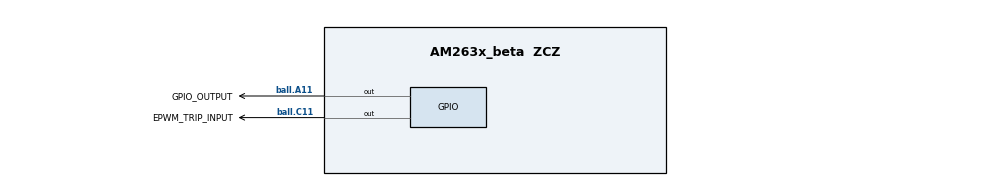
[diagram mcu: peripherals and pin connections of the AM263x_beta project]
/**
 * @cliArgs --device "AM263x_beta" --package "ZCZ" --part "AM263x" --context "r5fss0-0" --product "MCU_PLUS_SDK@07.03.01"
 * @versions {"tool":"1.13.0+2553"}
 */

/**
 * Import the modules used in this configuration.
 */
const epwm        = scripting.addModule("/drivers/epwm/epwm", {}, false);
const epwm1       = epwm.addInstance();
const epwm2       = epwm.addInstance();
const gpio        = scripting.addModule("/drivers/gpio/gpio", {}, false);
const gpio1       = gpio.addInstance();
const gpio2       = gpio.addInstance();
const mpu_armv7   = scripting.addModule("/kernel/dpl/mpu_armv7", {}, false);
const mpu_armv71  = mpu_armv7.addInstance();
const mpu_armv72  = mpu_armv7.addInstance();
const mpu_armv73  = mpu_armv7.addInstance();
const mpu_armv74  = mpu_armv7.addInstance();
const input_xbar  = scripting.addModule("/xbar/input_xbar/input_xbar", {}, false);
const input_xbar1 = input_xbar.addInstance();
const int_xbar    = scripting.addModule("/xbar/int_xbar/int_xbar", {}, false);
const int_xbar1   = int_xbar.addInstance();
const int_xbar2   = int_xbar.addInstance();

/**
 * Write custom configuration values to the imported modules.
 */
epwm1.epwmTimebase_emulationMode                                 = "EPWM_EMULATION_FREE_RUN";
epwm1.epwmTimebase_clockDiv                                      = "EPWM_CLOCK_DIVIDER_4";
epwm1.epwmTimebase_period                                        = 12000;
epwm1.epwmTimebase_counterMode                                   = "EPWM_COUNTER_MODE_UP_DOWN";
epwm1.epwmTimebase_syncOutPulseMode                              = ["EPWM_SYNC_OUT_PULSE_ON_ALL"];
epwm1.epwmCounterCompare_cmpA                                    = 6000;
epwm1.epwmActionQualifier_EPWM_AQ_OUTPUT_A_ON_TIMEBASE_UP_CMPA   = "EPWM_AQ_OUTPUT_HIGH";
epwm1.epwmActionQualifier_EPWM_AQ_OUTPUT_A_ON_TIMEBASE_DOWN_CMPA = "EPWM_AQ_OUTPUT_LOW";
epwm1.epwmEventTrigger_enableInterrupt                           = true;
epwm1.epwmEventTrigger_interruptEventCount                       = "1";
epwm1.epwmTimebase_hsClockDiv                                    = "EPWM_HSCLOCK_DIVIDER_4";
epwm1.epwmTripZone_oneShotSource                                 = ["EPWM_TZ_SIGNAL_OSHT1"];
epwm1.epwmTripZone_tzInterruptSource                             = ["EPWM_TZ_INTERRUPT_OST"];
epwm1.$name                                                      = "CONFIG_EPWMx";
epwm1.EPWM.$assign                                               = "EPWM9";
epwm1.EPWM.B.$used                                               = false;

epwm2.epwmTimebase_clockDiv                                      = "EPWM_CLOCK_DIVIDER_4";
epwm2.epwmTimebase_hsClockDiv                                    = "EPWM_HSCLOCK_DIVIDER_4";
epwm2.epwmTimebase_period                                        = 6000;
epwm2.epwmTimebase_counterMode                                   = "EPWM_COUNTER_MODE_UP_DOWN";
epwm2.epwmTimebase_emulationMode                                 = "EPWM_EMULATION_FREE_RUN";
epwm2.epwmTimebase_syncOutPulseMode                              = ["EPWM_SYNC_OUT_PULSE_ON_ALL"];
epwm2.epwmCounterCompare_cmpA                                    = 3000;
epwm2.epwmActionQualifier_EPWM_AQ_OUTPUT_A_ON_TIMEBASE_UP_CMPA   = "EPWM_AQ_OUTPUT_HIGH";
epwm2.epwmActionQualifier_EPWM_AQ_OUTPUT_A_ON_TIMEBASE_DOWN_CMPA = "EPWM_AQ_OUTPUT_LOW";
epwm2.epwmEventTrigger_enableInterrupt                           = true;
epwm2.epwmEventTrigger_interruptEventCount                       = "1";
epwm2.epwmTripZone_cbcSource                                     = ["EPWM_TZ_SIGNAL_CBC1"];
epwm2.epwmTripZone_tzInterruptSource                             = ["EPWM_TZ_INTERRUPT_CBC"];
epwm2.$name                                                      = "CONFIG_EPWMy";
epwm2.EPWM.$assign                                               = "EPWM1";
epwm2.EPWM.B.$used                                               = false;

gpio1.$name                = "EPWM_TRIP_INPUT";
gpio1.GPIO.gpioPin.$assign = "ball.C11";

gpio2.$name                = "GPIO_OUTPUT";
gpio2.pinDir               = "OUTPUT";
gpio2.trigType             = "RISE_EDGE";
gpio2.GPIO.gpioPin.$assign = "ball.A11";

mpu_armv71.$name             = "CONFIG_MPU_REGION0";
mpu_armv71.size              = 31;
mpu_armv71.attributes        = "Device";
mpu_armv71.accessPermissions = "Supervisor RD+WR, User RD";
mpu_armv71.allowExecute      = false;

mpu_armv72.$name             = "CONFIG_MPU_REGION1";
mpu_armv72.size              = 15;
mpu_armv72.accessPermissions = "Supervisor RD+WR, User RD";

mpu_armv73.$name             = "CONFIG_MPU_REGION2";
mpu_armv73.baseAddr          = 0x80000;
mpu_armv73.size              = 15;
mpu_armv73.accessPermissions = "Supervisor RD+WR, User RD";

mpu_armv74.$name             = "CONFIG_MPU_REGION3";
mpu_armv74.accessPermissions = "Supervisor RD+WR, User RD";
mpu_armv74.baseAddr          = 0x70000000;
mpu_armv74.size              = 21;

input_xbar1.$name      = "CONFIG_INPUT_XBAR0";
input_xbar1.xbarOutput = "GPIO11";

int_xbar1.$name      = "CONFIG_INT_XBAR0";
int_xbar1.xbarOutput = ["EPWM9_TZINT"];

int_xbar2.$name      = "CONFIG_INT_XBAR1";
int_xbar2.instance   = "INT_XBAR_1";
int_xbar2.xbarOutput = ["EPWM1_TZINT"];

/**
 * Pinmux solution for unlocked pins/peripherals. This ensures that minor changes to the automatic solver in a future
 * version of the tool will not impact the pinmux you originally saw.  These lines can be completely deleted in order to
 * re-solve from scratch.
 */
epwm1.EPWM.A.$suggestSolution = "ball.G1";
epwm2.EPWM.A.$suggestSolution = "ball.D3";
gpio1.GPIO.$suggestSolution   = "GPIO0";
gpio2.GPIO.$suggestSolution   = "GPIO0";
